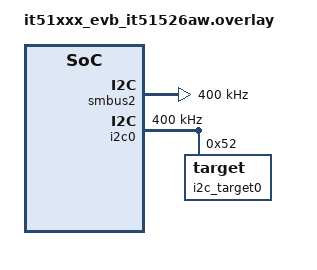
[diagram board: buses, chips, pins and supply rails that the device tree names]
/*
 * Copyright (c) 2026 ITE Corporation. All Rights Reserved.
 *
 * SPDX-License-Identifier: Apache-2.0
 */

/ {
	aliases {
		smbus-host = &smbus2;
		i2c-target = &i2c0;
	};
};

&smbus2 {
	status = "okay";
	clock-frequency = <I2C_BITRATE_FAST>;

	pinctrl-0 = <&i2c2_clk_gpf6_default
		     &i2c2_data_gpf7_default>;
	pinctrl-names = "default";
	fifo-enable;
};

&i2c0 {
	status = "okay";
	clock-frequency = <I2C_BITRATE_FAST>;
	pinctrl-0 = <&i2c0_clk_gpf2_default
		     &i2c0_data_gpf3_default>;
	pinctrl-names = "default";

	target-enable;
	target-shared-fifo-mode;

	i2c_target0: target@52 {
		reg = <0x52>;
		size = <256>;
	};
};
